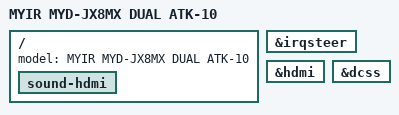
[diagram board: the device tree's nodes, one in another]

#include "myd-jx8mx-lcdif-atk-10-1.dts"

/ {
	model = "MYIR MYD-JX8MX DUAL  ATK-10";
	sound-hdmi {
		status = "okay";
	};
};

&irqsteer {
	status = "okay";
};

&hdmi {
	status = "okay";
};

&dcss {
	status = "okay";
};
